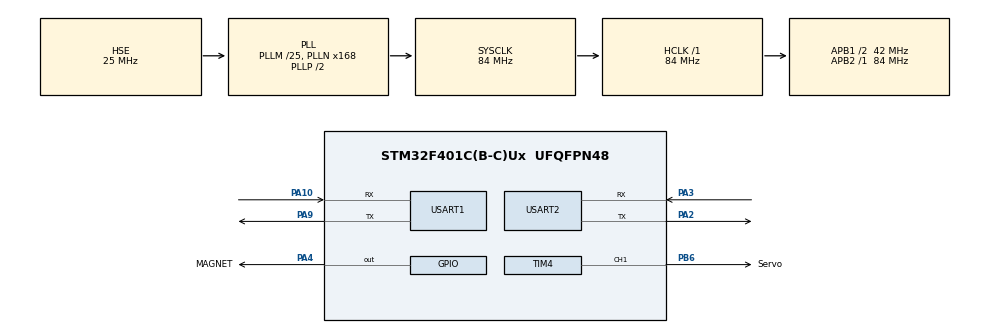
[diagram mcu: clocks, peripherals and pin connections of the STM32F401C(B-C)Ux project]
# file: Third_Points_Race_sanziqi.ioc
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Dma.Request0=USART2_RX
Dma.Request1=USART1_RX
Dma.USART1_RX.1.Direction=DMA_PERIPH_TO_MEMORY
Dma.USART1_RX.1.FIFOMode=DMA_FIFOMODE_DISABLE
Dma.USART1_RX.1.Instance=DMA2_Stream2
Dma.USART1_RX.1.MemDataAlignment=DMA_MDATAALIGN_BYTE
Dma.USART1_RX.1.MemInc=DMA_MINC_ENABLE
Dma.USART1_RX.1.Mode=DMA_NORMAL
Dma.USART1_RX.1.PeriphDataAlignment=DMA_PDATAALIGN_BYTE
Dma.USART1_RX.1.PeriphInc=DMA_PINC_DISABLE
Dma.USART1_RX.1.Priority=DMA_PRIORITY_LOW
Dma.USART2_RX.0.Direction=DMA_PERIPH_TO_MEMORY
Dma.USART2_RX.0.FIFOMode=DMA_FIFOMODE_DISABLE
Dma.USART2_RX.0.Instance=DMA1_Stream5
Dma.USART2_RX.0.MemDataAlignment=DMA_MDATAALIGN_BYTE
Dma.USART2_RX.0.MemInc=DMA_MINC_ENABLE
Dma.USART2_RX.0.Mode=DMA_NORMAL
Dma.USART2_RX.0.PeriphDataAlignment=DMA_PDATAALIGN_BYTE
Dma.USART2_RX.0.PeriphInc=DMA_PINC_DISABLE
Dma.USART2_RX.0.Priority=DMA_PRIORITY_LOW
Mcu.Family=STM32F4
Mcu.Name=STM32F401C(B-C)Ux
Mcu.Package=UFQFPN48
NVIC.DMA1_Stream5_IRQn=true\:0\:0\:false\:false\:true\:false\:true\:true
NVIC.DMA2_Stream2_IRQn=true\:0\:0\:false\:false\:true\:false\:true\:true
NVIC.PriorityGroup=NVIC_PRIORITYGROUP_4
NVIC.TIM1_UP_TIM10_IRQn=true\:1\:0\:true\:false\:true\:true\:true\:true
NVIC.TIM2_IRQn=true\:0\:0\:false\:false\:true\:true\:true\:true
NVIC.TIM3_IRQn=true\:0\:0\:false\:false\:true\:true\:true\:true
NVIC.TIM4_IRQn=true\:0\:0\:false\:false\:true\:true\:true\:true
NVIC.USART1_IRQn=true\:0\:0\:false\:false\:true\:true\:true\:true
PA10.Mode=Asynchronous
PA10.Signal=USART1_RX
PA13.Mode=Serial_Wire
PA13.Signal=SYS_JTMS-SWDIO
PA14.Mode=Serial_Wire
PA14.Signal=SYS_JTCK-SWCLK
PA2.Mode=Asynchronous
PA2.Signal=USART2_TX
PA3.Mode=Asynchronous
PA3.Signal=USART2_RX
PA4.GPIO_Label=MAGNET
PA4.Signal=GPIO_Output
PA9.Mode=Asynchronous
PA9.Signal=USART1_TX
PB6.GPIO_Label=Servo
PB6.Signal=S_TIM4_CH1
PH0\ -\ OSC_IN.Mode=HSE-External-Oscillator
PH0\ -\ OSC_IN.Signal=RCC_OSC_IN
PH1\ -\ OSC_OUT.Mode=HSE-External-Oscillator
PH1\ -\ OSC_OUT.Signal=RCC_OSC_OUT
ProjectManager.HeapSize=0x200
ProjectManager.StackSize=0x400
ProjectManager.TargetToolchain=MDK-ARM V5.32
RCC.48MHZClocksFreq_Value=42000000
RCC.AHBFreq_Value=84000000
RCC.APB1CLKDivider=RCC_HCLK_DIV2
RCC.APB1Freq_Value=42000000
RCC.APB1TimFreq_Value=84000000
RCC.APB2Freq_Value=84000000
RCC.APB2TimFreq_Value=84000000
RCC.CortexFreq_Value=84000000
RCC.HCLKFreq_Value=84000000
RCC.HSE_VALUE=25000000
RCC.HSI_VALUE=16000000
RCC.LSE_VALUE=32768
RCC.PLLM=25
RCC.PLLN=168
RCC.PLLSourceVirtual=RCC_PLLSOURCE_HSE
RCC.SYSCLKFreq_VALUE=84000000
RCC.SYSCLKSource=RCC_SYSCLKSOURCE_PLLCLK
RCC.VCOOutputFreq_Value=168000000
SH.S_TIM4_CH1.0=TIM4_CH1,PWM Generation1 CH1
TIM1.Period=10000-1
TIM1.Prescaler=84-1
TIM2.Period=1000-1
TIM2.Prescaler=84-1
TIM3.Period=1000-1
TIM3.Prescaler=84-1
TIM4.Channel-PWM\ Generation1\ CH1=TIM_CHANNEL_1
TIM4.Period=20000-1
TIM4.Prescaler=84-1
USART1.VirtualMode=VM_ASYNC
USART2.VirtualMode=VM_ASYNC
VP_TIM1_VS_ClockSourceINT.Mode=Internal
VP_TIM2_VS_ClockSourceINT.Mode=Internal
VP_TIM3_VS_ClockSourceINT.Mode=Internal
VP_TIM4_VS_ClockSourceINT.Mode=Internal
board=custom

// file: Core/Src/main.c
/* USER CODE BEGIN Header */
/**
  ******************************************************************************
  * @file           : main.c
  * @brief          : Main program body
  ******************************************************************************
  * @attention
  *
  * Copyright (c) 2025 STMicroelectronics.
  * All rights reserved.
  *
  * This software is licensed under terms that can be found in the LICENSE file
  * in the root directory of this software component.
  * If no LICENSE file comes with this software, it is provided AS-IS.
  *
  ******************************************************************************
  */
/* USER CODE END Header */
#include "main.h"
#include "dma.h"
#include "tim.h"
#include "usart.h"
#include "gpio.h"

/* USER CODE BEGIN Includes */
#include "bsp_uart.h"
#include "Emm_V5.h"
#include "bsp_dwt.h"
#include "system.h"
#include "decode.h"
/* USER CODE END Includes */

/* USER CODE BEGIN PV */
extern DMA_HandleTypeDef hdma_usart1_rx;
extern DMA_HandleTypeDef hdma_usart2_rx;
/* USER CODE END PV */

void SystemClock_Config(void);

/* USER CODE BEGIN 0 */
// Command_t temp_cmd;
// 	uint8_t src_idx = 0;
// 	uint8_t dst_idx = 0;
// 	uint8_t res = 0;
// 	uint8_t count = 0;

/* USER CODE END 0 */

int main(void)
{

  /* MCU Configuration--------------------------------------------------------*/

  /* Reset of all peripherals, Initializes the Flash interface and the Systick. */
  HAL_Init();

  /* Configure the system clock */
  SystemClock_Config();

  /* Initialize all configured peripherals */
  MX_GPIO_Init();
  MX_DMA_Init();
  MX_USART1_UART_Init();
  MX_TIM2_Init();
  MX_TIM1_Init();
  MX_TIM3_Init();
  MX_TIM4_Init();
  MX_USART2_UART_Init();
  /* USER CODE BEGIN 2 */
	DWT_Init(84);

  //HAL_UARTEx_ReceiveToIdle_DMA(&huart1, rx2_buffer, DMA_BUFFER);
  HAL_UARTEx_ReceiveToIdle_DMA(&huart2, rx2_buffer, DMA_BUFFER);

  //__HAL_DMA_DISABLE_IT(&hdma_usart1_rx, DMA_IT_HT);

	HAL_TIM_Base_Start_IT(&htim2);
	//HAL_TIM_Base_Start_IT(&htim3);

	HAL_TIM_PWM_Start(&htim4, TIM_CHANNEL_1);

	  __HAL_DMA_DISABLE_IT(&hdma_usart2_rx, DMA_IT_HT);

//		__HAL_TIM_SetCompare(&htim4,TIM_CHANNEL_1,2400);
		HAL_UART_Receive_IT(&huart1, &rx_byte, 1);

	// ��ʱ��ŵ�uart�ж�����һ��ĵ�

	Place_Chess_Start(4, 6);
  /* USER CODE END 2 */

  /* Infinite loop */
  /* USER CODE BEGIN WHILE */
  while (1)
  {
//		if(robot.system_state == SYSTEM_IDLE){
//			Place_Chess_Start(2, 3);
//	}

    /* USER CODE END WHILE */

    /* USER CODE BEGIN 3 */
//		res = dequeue_command(&temp_cmd,0);
//		if(res){
//		src_idx = temp_cmd.src;
//		dst_idx = temp_cmd.dst;
//			count++;
//		}
  }
  /* USER CODE END 3 */
}

void SystemClock_Config(void)
{
  RCC_OscInitTypeDef RCC_OscInitStruct = {0};
  RCC_ClkInitTypeDef RCC_ClkInitStruct = {0};

  /** Configure the main internal regulator output voltage
  */
  __HAL_RCC_PWR_CLK_ENABLE();
  __HAL_PWR_VOLTAGESCALING_CONFIG(PWR_REGULATOR_VOLTAGE_SCALE2);

  /** Initializes the RCC Oscillators according to the specified parameters
  * in the RCC_OscInitTypeDef structure.
  */
  RCC_OscInitStruct.OscillatorType = RCC_OSCILLATORTYPE_HSE;
  RCC_OscInitStruct.HSEState = RCC_HSE_ON;
  RCC_OscInitStruct.PLL.PLLState = RCC_PLL_ON;
  RCC_OscInitStruct.PLL.PLLSource = RCC_PLLSOURCE_HSE;
  RCC_OscInitStruct.PLL.PLLM = 25;
  RCC_OscInitStruct.PLL.PLLN = 168;
  RCC_OscInitStruct.PLL.PLLP = RCC_PLLP_DIV2;
  RCC_OscInitStruct.PLL.PLLQ = 4;
  if (HAL_RCC_OscConfig(&RCC_OscInitStruct) != HAL_OK)
  {
    Error_Handler();
  }

  /** Initializes the CPU, AHB and APB buses clocks
  */
  RCC_ClkInitStruct.ClockType = RCC_CLOCKTYPE_HCLK|RCC_CLOCKTYPE_SYSCLK
                              |RCC_CLOCKTYPE_PCLK1|RCC_CLOCKTYPE_PCLK2;
  RCC_ClkInitStruct.SYSCLKSource = RCC_SYSCLKSOURCE_PLLCLK;
  RCC_ClkInitStruct.AHBCLKDivider = RCC_SYSCLK_DIV1;
  RCC_ClkInitStruct.APB1CLKDivider = RCC_HCLK_DIV2;
  RCC_ClkInitStruct.APB2CLKDivider = RCC_HCLK_DIV1;

  if (HAL_RCC_ClockConfig(&RCC_ClkInitStruct, FLASH_LATENCY_2) != HAL_OK)
  {
    Error_Handler();
  }
}

void Error_Handler(void)
{
  __disable_irq();
  while (1)
  {
  }
}
